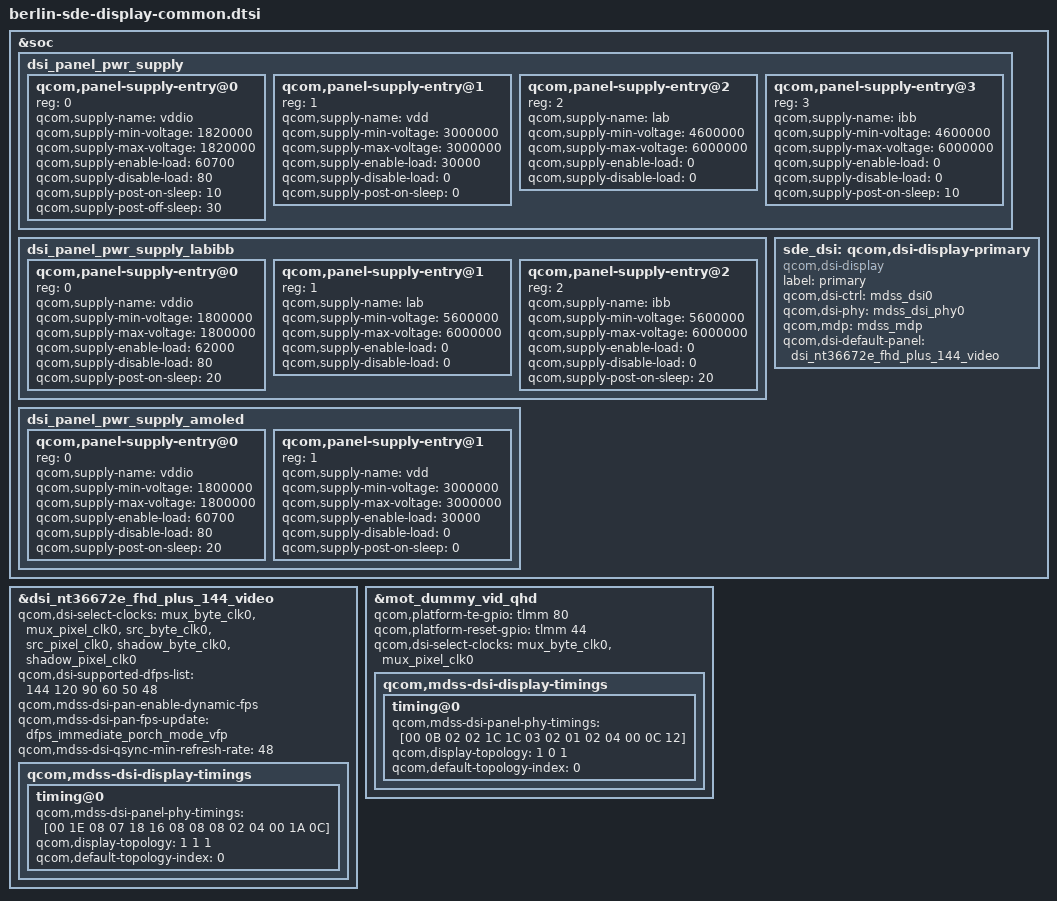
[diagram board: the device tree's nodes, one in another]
#include "dsi-panel-mot-tiamma-nt36672e-678-1080p-video-common.dtsi"
#include "dsi-panel-mot-dummy-qhd-video.dtsi"
#include <dt-bindings/clock/mdss-5nm-pll-clk.h>

&soc {
	dsi_panel_pwr_supply: dsi_panel_pwr_supply {
		#address-cells = <1>;
		#size-cells = <0>;

		qcom,panel-supply-entry@0 {
			reg = <0>;
			qcom,supply-name = "vddio";
			qcom,supply-min-voltage = <1820000>;
			qcom,supply-max-voltage = <1820000>;
			qcom,supply-enable-load = <60700>;
			qcom,supply-disable-load = <80>;
			qcom,supply-post-on-sleep = <10>;
			qcom,supply-post-off-sleep = <30>;
		};

		qcom,panel-supply-entry@1 {
			reg = <1>;
			qcom,supply-name = "vdd";
			qcom,supply-min-voltage = <3000000>;
			qcom,supply-max-voltage = <3000000>;
			qcom,supply-enable-load = <30000>;
			qcom,supply-disable-load = <0>;
			qcom,supply-post-on-sleep = <0>;
		};

		qcom,panel-supply-entry@2 {
			reg = <2>;
			qcom,supply-name = "lab";
			qcom,supply-min-voltage = <4600000>;
			qcom,supply-max-voltage = <6000000>;
			qcom,supply-enable-load = <0>;
			qcom,supply-disable-load = <0>;
		};

		qcom,panel-supply-entry@3 {
			reg = <3>;
			qcom,supply-name = "ibb";
			qcom,supply-min-voltage = <4600000>;
			qcom,supply-max-voltage = <6000000>;
			qcom,supply-enable-load = <0>;
			qcom,supply-disable-load = <0>;
			qcom,supply-post-on-sleep = <10>;
		};
	};

	dsi_panel_pwr_supply_labibb: dsi_panel_pwr_supply_labibb {
		#address-cells = <1>;
		#size-cells = <0>;

		qcom,panel-supply-entry@0 {
			reg = <0>;
			qcom,supply-name = "vddio";
			qcom,supply-min-voltage = <1800000>;
			qcom,supply-max-voltage = <1800000>;
			qcom,supply-enable-load = <62000>;
			qcom,supply-disable-load = <80>;
			qcom,supply-post-on-sleep = <20>;
		};

		qcom,panel-supply-entry@1 {
			reg = <1>;
			qcom,supply-name = "lab";
			qcom,supply-min-voltage = <5600000>;
			qcom,supply-max-voltage = <6000000>;
			qcom,supply-enable-load = <0>;
			qcom,supply-disable-load = <0>;
		};

		qcom,panel-supply-entry@2 {
			reg = <2>;
			qcom,supply-name = "ibb";
			qcom,supply-min-voltage = <5600000>;
			qcom,supply-max-voltage = <6000000>;
			qcom,supply-enable-load = <0>;
			qcom,supply-disable-load = <0>;
			qcom,supply-post-on-sleep = <20>;
		};
	};

	dsi_panel_pwr_supply_amoled: dsi_panel_pwr_supply_amoled {
		#address-cells = <1>;
		#size-cells = <0>;

		qcom,panel-supply-entry@0 {
			reg = <0>;
			qcom,supply-name = "vddio";
			qcom,supply-min-voltage = <1800000>;
			qcom,supply-max-voltage = <1800000>;
			qcom,supply-enable-load = <60700>;
			qcom,supply-disable-load = <80>;
			qcom,supply-post-on-sleep = <20>;
		};

		qcom,panel-supply-entry@1 {
			reg = <1>;
			qcom,supply-name = "vdd";
			qcom,supply-min-voltage = <3000000>;
			qcom,supply-max-voltage = <3000000>;
			qcom,supply-enable-load = <30000>;
			qcom,supply-disable-load = <0>;
			qcom,supply-post-on-sleep = <0>;
		};
	};

	sde_dsi: qcom,dsi-display-primary {
		compatible = "qcom,dsi-display";
		label = "primary";

		qcom,dsi-ctrl = <&mdss_dsi0>;
		qcom,dsi-phy = <&mdss_dsi_phy0>;

		qcom,mdp = <&mdss_mdp>;
		qcom,dsi-default-panel = <&dsi_nt36672e_fhd_plus_144_video>;
	};
};

&dsi_nt36672e_fhd_plus_144_video {
	qcom,dsi-select-clocks = "mux_byte_clk0", "mux_pixel_clk0",
				"src_byte_clk0", "src_pixel_clk0",
				"shadow_byte_clk0", "shadow_pixel_clk0";
	qcom,dsi-supported-dfps-list = <144 120 90 60 50 48>;
	qcom,mdss-dsi-pan-enable-dynamic-fps;
	qcom,mdss-dsi-pan-fps-update = "dfps_immediate_porch_mode_vfp";
	qcom,mdss-dsi-qsync-min-refresh-rate = <48>;
	qcom,mdss-dsi-display-timings {
		timing@0 {
			qcom,mdss-dsi-panel-phy-timings = [00 1E 08 07 18 16 08
				08 08 02 04 00 1A 0C];
			qcom,display-topology = <1 1 1>;
			qcom,default-topology-index = <0>;
		};
	};
};

&mot_dummy_vid_qhd {
	qcom,platform-te-gpio = <&tlmm 80 0>;
	qcom,platform-reset-gpio = <&tlmm 44 0>;

	qcom,dsi-select-clocks = "mux_byte_clk0", "mux_pixel_clk0";
	qcom,mdss-dsi-display-timings {
		timing@0 {
			qcom,mdss-dsi-panel-phy-timings = [00 0B 02 02 1C 1C 03
							02 01 02 04 00 0C 12];
			qcom,display-topology = <1 0 1>;
			qcom,default-topology-index = <0>;
		};
	};
};
